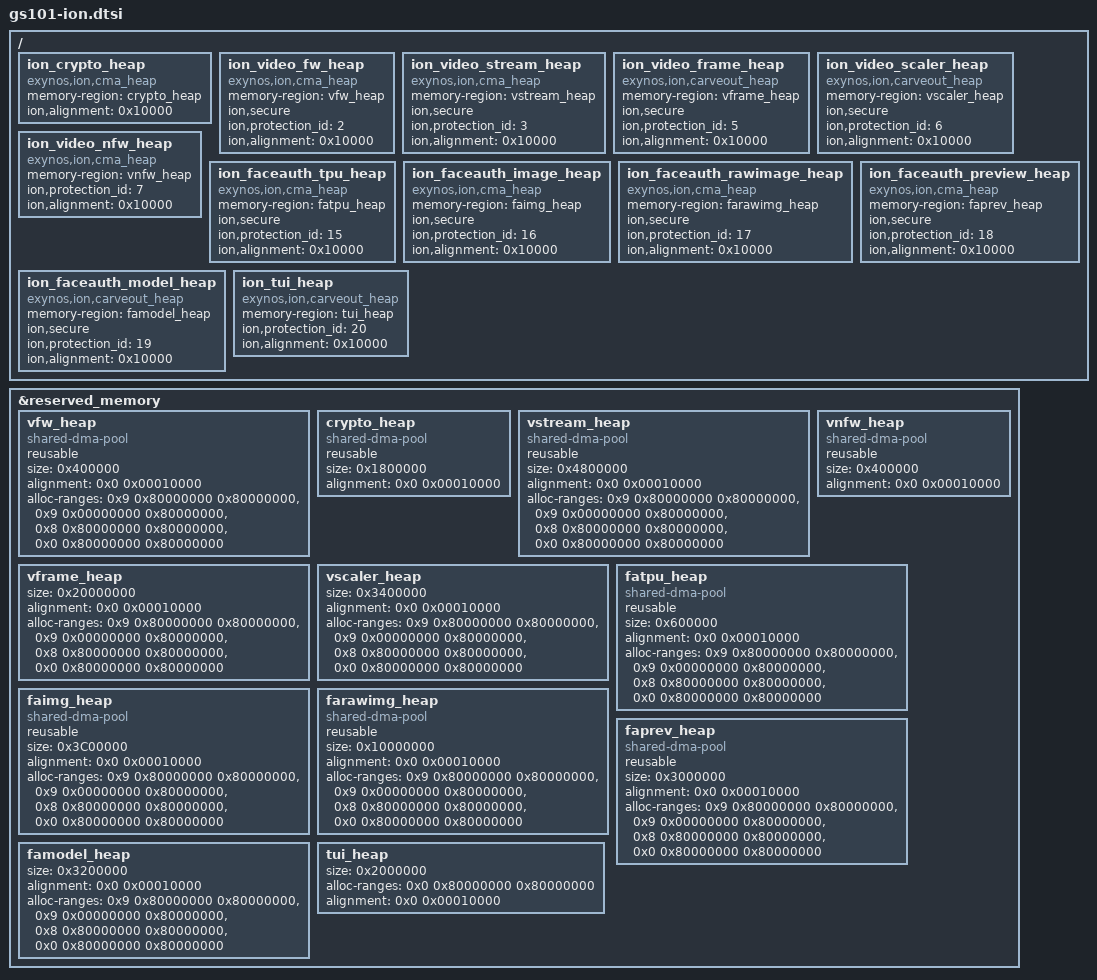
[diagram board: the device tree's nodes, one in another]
// SPDX-License-Identifier: GPL-2.0-only
/*
 * GS101 SoC ION
 *
 * Copyright 2019 Google LLC
 */

/ {
	ion_crypto_heap {
		compatible = "exynos,ion,cma_heap";
		memory-region = <&crypto_heap>;
		ion,alignment = <0x10000>;
	};

	ion_video_fw_heap {
		compatible = "exynos,ion,cma_heap";
		memory-region = <&vfw_heap>;
		ion,secure;
		ion,protection_id = <2>;
		ion,alignment = <0x10000>;
	};

	ion_video_stream_heap {
		compatible = "exynos,ion,cma_heap";
		memory-region = <&vstream_heap>;
		ion,secure;
		ion,protection_id = <3>;
		ion,alignment = <0x10000>;
	};

	ion_video_frame_heap {
		compatible = "exynos,ion,carveout_heap";
		memory-region = <&vframe_heap>;
		ion,secure;
		ion,protection_id = <5>;
		ion,alignment = <0x10000>;
	};

	ion_video_scaler_heap {
		compatible = "exynos,ion,carveout_heap";
		memory-region = <&vscaler_heap>;
		ion,secure;
		ion,protection_id = <6>;
		ion,alignment = <0x10000>;
	};

	ion_video_nfw_heap {
		compatible = "exynos,ion,cma_heap";
		memory-region = <&vnfw_heap>;
		ion,protection_id = <7>;
		ion,alignment = <0x10000>;
	};

	ion_faceauth_tpu_heap {
		compatible = "exynos,ion,cma_heap";
		memory-region = <&fatpu_heap>;
		ion,secure;
		ion,protection_id = <15>;
		ion,alignment = <0x10000>;
	};

	ion_faceauth_image_heap {
		compatible = "exynos,ion,cma_heap";
		memory-region = <&faimg_heap>;
		ion,secure;
		ion,protection_id = <16>;
		ion,alignment = <0x10000>;
	};

	ion_faceauth_rawimage_heap {
		compatible = "exynos,ion,cma_heap";
		memory-region = <&farawimg_heap>;
		ion,secure;
		ion,protection_id = <17>;
		ion,alignment = <0x10000>;
	};

	ion_faceauth_preview_heap {
		compatible = "exynos,ion,cma_heap";
		memory-region = <&faprev_heap>;
		ion,secure;
		ion,protection_id = <18>;
		ion,alignment = <0x10000>;
	};

	ion_faceauth_model_heap {
		compatible = "exynos,ion,carveout_heap";
		memory-region = <&famodel_heap>;
		ion,secure;
		ion,protection_id = <19>;
		ion,alignment = <0x10000>;
	};

	ion_tui_heap {
		compatible = "exynos,ion,carveout_heap";
		memory-region = <&tui_heap>;
		ion,protection_id = <20>;
		ion,alignment = <0x10000>;
	};
};

&reserved_memory {
	#address-cells = <2>;
	#size-cells = <1>;

	vfw_heap: vfw_heap {
		compatible = "shared-dma-pool";
		reusable;
		size = <0x400000>;
		alignment = <0x0 0x00010000>;
		alloc-ranges = <0x9 0x80000000 0x80000000>,
			       <0x9 0x00000000 0x80000000>,
			       <0x8 0x80000000 0x80000000>,
			       <0x0 0x80000000 0x80000000>;
	};

	crypto_heap: crypto_heap {
		compatible = "shared-dma-pool";
		reusable;
		size = <0x1800000>;
		alignment = <0x0 0x00010000>;
	};

	vstream_heap: vstream_heap {
		compatible = "shared-dma-pool";
		reusable;
		size = <0x4800000>;
		alignment = <0x0 0x00010000>;
		alloc-ranges = <0x9 0x80000000 0x80000000>,
			       <0x9 0x00000000 0x80000000>,
			       <0x8 0x80000000 0x80000000>,
			       <0x0 0x80000000 0x80000000>;
	};

	vframe_heap: vframe_heap {
		size = <0x20000000>;
		alignment = <0x0 0x00010000>;
		alloc-ranges = <0x9 0x80000000 0x80000000>,
			       <0x9 0x00000000 0x80000000>,
			       <0x8 0x80000000 0x80000000>,
			       <0x0 0x80000000 0x80000000>;
	};

	vscaler_heap: vscaler_heap {
		size = <0x3400000>;
		alignment = <0x0 0x00010000>;
		alloc-ranges = <0x9 0x80000000 0x80000000>,
			       <0x9 0x00000000 0x80000000>,
			       <0x8 0x80000000 0x80000000>,
			       <0x0 0x80000000 0x80000000>;
	};

	vnfw_heap: vnfw_heap {
		compatible = "shared-dma-pool";
		reusable;
		size = <0x400000>;
		alignment = <0x0 0x00010000>;
	};

	fatpu_heap: fatpu_heap {
		compatible = "shared-dma-pool";
		reusable;
		size = <0x600000>;
		alignment = <0x0 0x00010000>;
		alloc-ranges = <0x9 0x80000000 0x80000000>,
			       <0x9 0x00000000 0x80000000>,
			       <0x8 0x80000000 0x80000000>,
			       <0x0 0x80000000 0x80000000>;
	};

	faimg_heap: faimg_heap {
		compatible = "shared-dma-pool";
		reusable;
		size = <0x3C00000>;
		alignment = <0x0 0x00010000>;
		alloc-ranges = <0x9 0x80000000 0x80000000>,
			       <0x9 0x00000000 0x80000000>,
			       <0x8 0x80000000 0x80000000>,
			       <0x0 0x80000000 0x80000000>;
	};

	farawimg_heap: farawimg_heap {
		compatible = "shared-dma-pool";
		reusable;
		size = <0x10000000>;
		alignment = <0x0 0x00010000>;
		alloc-ranges = <0x9 0x80000000 0x80000000>,
			       <0x9 0x00000000 0x80000000>,
			       <0x8 0x80000000 0x80000000>,
			       <0x0 0x80000000 0x80000000>;
	};

	faprev_heap: faprev_heap {
		compatible = "shared-dma-pool";
		reusable;
		size = <0x3000000>;
		alignment = <0x0 0x00010000>;
		alloc-ranges = <0x9 0x80000000 0x80000000>,
			       <0x9 0x00000000 0x80000000>,
			       <0x8 0x80000000 0x80000000>,
			       <0x0 0x80000000 0x80000000>;
	};

	famodel_heap: famodel_heap {
		size = <0x3200000>;
		alignment = <0x0 0x00010000>;
		alloc-ranges = <0x9 0x80000000 0x80000000>,
			       <0x9 0x00000000 0x80000000>,
			       <0x8 0x80000000 0x80000000>,
			       <0x0 0x80000000 0x80000000>;
	};

	tui_heap: tui_heap {
		size = <0x2000000>;
		alloc-ranges = <0x0 0x80000000 0x80000000>;
		alignment = <0x0 0x00010000>;
	};
};
